# MKE02Z2 register map
File version: 1.6
Registers are 32-bit, read-write, reset 0x0 unless marked. A register's access mark holds for its fields unless they carry their own. Offsets are from the block's base; [hi:lo] are bit positions; 'fields as' and 'values as' point back to an identical list.

## ICS — Clock management
Base 0x40064000; register names take the prefix ICS_
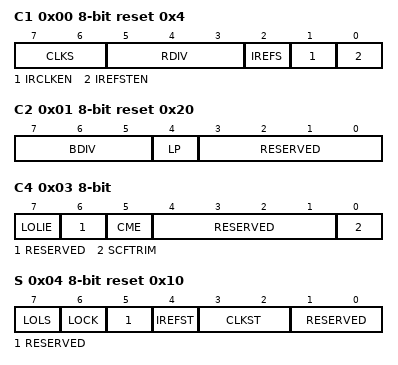
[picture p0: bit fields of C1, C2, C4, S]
0x00 C1 8-bit reset 0x4 — ICS Control Register 1
  [7:6] CLKS — Clock Source Select
    0=Output of FLL is selected; 1=Internal reference clock is selected; 2=External reference clock is selected; 3=Reserved, defaults to 00
  [5:3] RDIV — Reference Divider
  [2] IREFS — Internal Reference Select
    0=External reference clock is selected; 1=Internal reference clock is selected
  [1] IRCLKEN — Internal Reference Clock Enable
    0=ICSIRCLK is inactive; 1=ICSIRCLK is active
  [0] IREFSTEN — Internal Reference Stop Enable
    0=Internal reference clock is disabled in Stop mode; 1=Internal reference clock stays enabled in Stop mode if IRCLKEN is set, or if ICS is in FEI, FBI, or FBILP mode before entering Stop
0x01 C2 8-bit reset 0x20 — ICS Control Register 2
  [7:5] BDIV — Bus Frequency Divider
    0=Encoding 0-Divides the selected clock by 1; 1=Encoding 1-Divides the selected clock by 2 (reset default); 2=Encoding 2-Divides the selected clock by 4; 3=Encoding 3-Divides the selected clock by 8; 4=Encoding 4-Divides the selected clock by 16; 5=Encoding 5-Divides the selected clock by 32; 6=Encoding 6-Divides the selected clock by 64; 7=Encoding 7-Divides the selected clock by 128
  [4] LP — Low Power Select
    0=FLL is not disabled in bypass mode; 1=FLL is disabled in bypass modes unless BDM is active
  [3:0] RESERVED ro
0x02 C3 8-bit reset not defined — ICS Control Register 3
  [7:0] SCTRIM — Slow Internal Reference Clock Trim Setting
0x03 C4 8-bit — ICS Control Register 4
  [7] LOLIE — Loss of Lock Interrupt
    0=No request on loss of lock; 1=Generates an interrupt request on loss of lock
  [6] RESERVED ro
  [5] CME — Clock Monitor Enable
    0=Clock monitor is disabled; 1=Generates a reset request on loss of external clock
  [4:1] RESERVED ro
  [0] SCFTRIM — Slow Internal Reference Clock Fine Trim
0x04 S 8-bit ro reset 0x10 — ICS Status Register
  [7] LOLS — Loss of Lock Status
    0=FLL has not lost lock since LOLS was last cleared; 1=FLL has lost lock since LOLS was last cleared
  [6] LOCK — Lock Status
    0=FLL is currently unlocked; 1=FLL is currently locked
  [5] RESERVED
  [4] IREFST — Internal Reference Status
    0=Source of reference clock is external clock; 1=Source of reference clock is internal clock
  [3:2] CLKST — Clock Mode Status
    0=Output of FLL is selected; 1=FLL Bypassed, internal reference clock is selected; 2=FLL Bypassed, external reference clock is selected
  [1:0] RESERVED

## OSC — Oscillator
Base 0x40065000; register names take the prefix OSC_
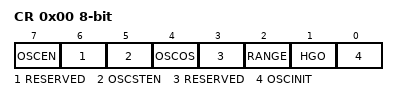
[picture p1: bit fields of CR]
0x00 CR 8-bit — OSC Control Register
  [7] OSCEN — OSC Enable
    0=OSC module is disabled; 1=OSC module is enabled
  [6] RESERVED ro
  [5] OSCSTEN — OSC Enable in Stop mode
    0=OSC clock is disabled in Stop mode; 1=OSC clock stays enabled in Stop mode
  [4] OSCOS — OSC Output Select
    0=External clock source from EXTAL pin is selected; 1=Oscillator clock source is selected
  [3] RESERVED ro
  [2] RANGE — Frequency Range Select
    0=Low frequency range of 32 kHz; 1=High frequency range of 4-20 MHz
  [1] HGO — High Gain Oscillator Select
    0=Low-power mode; 1=High-gain mode
  [0] OSCINIT ro — OSC Initialization
    0=Oscillator initialization is not complete; 1=Oscillator initialization is completed

## ACMP0 — Analog comparator
Base 0x40073000; register names take the prefix ACMP0_
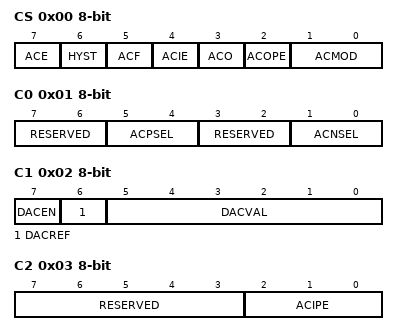
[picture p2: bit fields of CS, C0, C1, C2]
0x00 CS 8-bit — ACMP Control and Status Register
  [7] ACE — Analog Comparator Enable
    0=The ACMP is disabled; 1=The ACMP is enabled
  [6] HYST — Analog Comparator Hystersis Selection
    0=20 mV; 1=30 mV
  [5] ACF — ACMP Interrupt Flag Bit
  [4] ACIE — ACMP Interrupt Enable
    0=Disable the ACMP Interrupt; 1=Enable the ACMP Interrupt
  [3] ACO ro — ACMP Output
  [2] ACOPE — ACMP Output Pin Enable
    0=ACMP output cannot be placed onto external pin; 1=ACMP output can be placed onto external pin
  [1:0] ACMOD — ACMP MOD
    0=ACMP interrupt on output falling edge; 1=ACMP interrupt on output rising edge; 2=ACMP interrupt on output falling edge; 3=ACMP interrupt on output falling or rising edge
0x01 C0 8-bit — ACMP Control Register 0
  [7:6] RESERVED ro
  [5:4] ACPSEL — ACMP Positive Input Select
    0=External reference 0; 1=External reference 1; 2=External reference 2; 3=DAC output
  [3:2] RESERVED ro
  [1:0] ACNSEL — ACMP Negative Input Select
    values as ACPSEL
0x02 C1 8-bit — ACMP Control Register 1
  [7] DACEN — DAC Enable
    0=The DAC is disabled; 1=The DAC is enabled
  [6] DACREF — DAC Reference Select
    0=The DAC selects Bandgap as the reference; 1=The DAC selects VDDA as the reference
  [5:0] DACVAL — DAC Output Level Selection
0x03 C2 8-bit — ACMP Control Register 2
  [7:3] RESERVED ro
  [2:0] ACIPE — ACMP Input Pin Enable
    0=The corresponding external analog input is not allowed; 1=The corresponding external analog input is allowed

## ACMP1 — Analog comparator
Base 0x40074000; register names take the prefix ACMP1_
Registers as ACMP0.
